# CH32L103 register map
Vendor: WCH Ltd.; File version: 1.3
Registers are 32-bit, read-write, reset 0x0 unless marked. A register's access mark holds for its fields unless they carry their own. Offsets are from the block's base; [hi:lo] are bit positions.

## LPTIM — Low-power timer
Base 0x40007C00
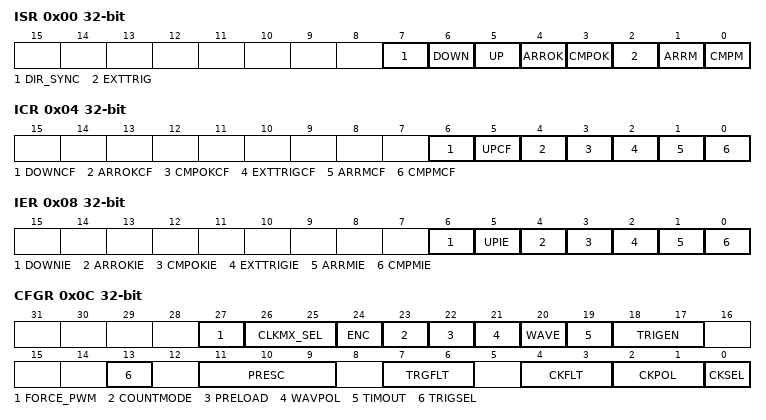
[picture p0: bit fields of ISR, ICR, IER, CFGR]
0x00 ISR ro — interrupt status register
  [7] DIR_SYNC — direction of count
  [6] DOWN — count down
  [5] UP — count-up
  [4] ARROK — Aoto-reload register data update successfully
  [3] CMPOK — compare register data update successfully
  [2] EXTTRIG — Edge event are triggerd externally
  [1] ARRM — DATA of Aoto-reload register and LPTIM_CNT match
  [0] CMPM — DATA of compare register and LPTIM_CNT match
0x04 ICR wo — interrupt clear register
  [6] DOWNCF — clear down flag
  [5] UPCF — clear up flag
  [4] ARROKCF — clear Aoto-reload register data update flag
  [3] CMPOKCF — clear compare register data update flag
  [2] EXTTRIGCF — clear Edge event are triggerd externally flag
  [1] ARRMCF — clear Aoto-reload register match flag
  [0] CMPMCF — clear compare register match flag
0x08 IER — interrupt enable register
  [6] DOWNIE — Down interrupt enable
  [5] UPIE — UP interrupt enable
  [4] ARROKIE — Aoto-reload register data update successfully interrupts enable
  [3] CMPOKIE — compare register data update successfully interrupts enable
  [2] EXTTRIGIE — Edge event are triggerd externally successfully interrupts enable
  [1] ARRMIE — Aoto-reload register match successfully interrupts enable
  [0] CMPMIE — compare register match successfully interrupts enable
0x0C CFGR — configuration register
  [27] FORCE_PWM — Forcing pwm output
  [26:25] CLKMX_SEL — clock selection
  [24] ENC — coder mode
  [23] COUNTMODE — count clock selection
  [22] PRELOAD — update mode control
  [21] WAVPOL — PWM polarity
  [20] WAVE — PWM
  [19] TIMOUT — TIMEOUT control
  [18:17] TRIGEN — trigger configuration
  [13] TRIGSEL — trigger source selection
  [11:9] PRESC — prescaler configuration
  [7:6] TRGFLT — digital filter for flip-flops
  [4:3] CKFLT — digital filter for ex-clock
  [2:1] CKPOL — configure effective edges
  [0] CKSEL — effective edge configuration
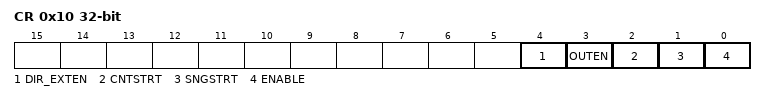
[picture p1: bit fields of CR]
0x10 CR — control register
  [4] DIR_EXTEN — externally trigger count direction enable
  [3] OUTEN — pwm output enable
  [2] CNTSTRT — start in continuous mode
  [1] SNGSTRT — start in one trigger mode
  [0] ENABLE — timer enable
0x14 CMP — compare register
  [15:0] CMP — compare value
0x18 ARR reset 0x1 — aoto-reload register
  [15:0] ARR — aoto-reload count value
0x1C CNT — COUNT register
  [15:0] COUNT — Timer count value

## USBPD — USBPD control register
Base 0x40027000
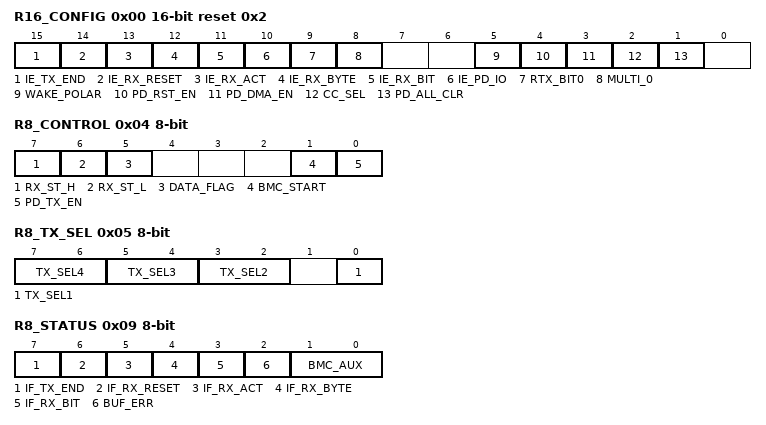
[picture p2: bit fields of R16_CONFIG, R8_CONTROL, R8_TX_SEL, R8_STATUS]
0x00 R16_CONFIG 16-bit reset 0x2 — PD configuration register
  [15] IE_TX_END — end of send interrupt enable
  [14] IE_RX_RESET — receive reset interrupt enable
  [13] IE_RX_ACT — receive finished interrupt enable
  [12] IE_RX_BYTE — receive byte interrupt enable
  [11] IE_RX_BIT — receive bit interrupt enable
  [10] IE_PD_IO — PD port interrupt enable
  [9] RTX_BIT0 — Send and receive the current value of shift register bit0
  [8] MULTI_0 — Receive a continuous multi-digit0 indication signal
  [5] WAKE_POLAR — wake-up level
  [4] PD_RST_EN — reset enable
  [3] PD_DMA_EN — PD_DMA enable
  [2] CC_SEL — communication port selection
  [1] PD_ALL_CLR — clear all interrupt enable
0x02 R16_BMC_CLK_CNT 16-bit — BMC sample clock counter
  [8:0] BMC_CLK_CNT — BMC sent/receive sample clock counter
0x04 R8_CONTROL 8-bit — sent/receive enable register
  [7] RX_ST_H — receive status high bit
  [6] RX_ST_L — receive status low bit
  [5] DATA_FLAG — data cache valid flag
  [1] BMC_START — BMC send a start signal
  [0] PD_TX_EN — sent/receive enable
0x05 R8_TX_SEL 8-bit — PD send sop selection register
  [7:6] TX_SEL4 — PD send type selection
  [5:4] TX_SEL3 — PD send type selection
  [3:2] TX_SEL2 — PD send type selection
  [0] TX_SEL1 — PD send type selection
0x06 R16_BMC_TX_SZ 16-bit — Total length sent
  [8:0] BMC_TX_SZ
0x08 R8_DATA_BUF 8-bit — DMA buffer data register
  [7:0] DATA_BUF — DMA DATA_BUFFER
0x09 R8_STATUS 8-bit access per field — PD interrupt flag register
  [7] IF_TX_END rw — Transmission completed interrupt flag
  [6] IF_RX_RESET rw — Receive reset interrupt flag
  [5] IF_RX_ACT rw — Receive completed interrupt flag
  [4] IF_RX_BYTE rw — Receive byte/SOP interrupt flag
  [3] IF_RX_BIT rw — Receive BIT/5BIT interrupt flag
  [2] BUF_ERR rw — BUFFER/DMA error interrupt flag
  [1:0] BMC_AUX ro — Indicating the current state
0x0A R16_BMC_BYTE_CNT 16-bit ro — byte count register
  [8:0] BMC_BYTE_CNT
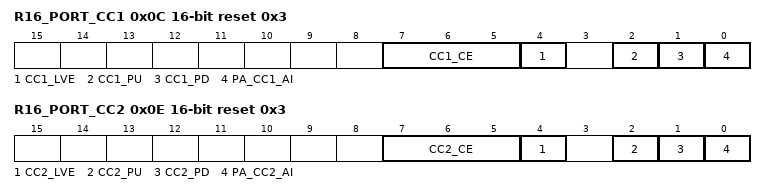
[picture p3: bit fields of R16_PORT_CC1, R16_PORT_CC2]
0x0C R16_PORT_CC1 16-bit reset 0x3 — port control register
  [7:5] CC1_CE — Enable port voltage comparator
  [4] CC1_LVE — port output lower voltage enable
  [2] CC1_PU — port pull-up current enable
  [1] CC1_PD — port pull-down resistor enable
  [0] PA_CC1_AI — port comparator simulates input
0x0E R16_PORT_CC2 16-bit reset 0x3 — port control register
  [7:5] CC2_CE — Enable port voltage comparator
  [4] CC2_LVE — port output lower voltage enable
  [2] CC2_PU — port pull-up current enable
  [1] CC2_PD — port pull-down resistor enable
  [0] PA_CC2_AI — port comparator simulates input
0x10 R16_DMA 16-bit — DMA cache start address register
  [15:0] USBPD_DMA_ADDR — USBPD_DMA cache address

## ESIG — ESIG configuration
Base 0x1FFFF7E0
0x00 FLACAP 16-bit ro — Flash capecity register
  [15:0] F_SIZE — F_SIZE/kByte
0x08 UNIID1 ro — UID register
  [31:0] U_ID — U_ID value
0x0C UNIID2 ro — UID register
  [31:0] U_ID — U_ID value
0x10 UNIID3 ro — Div register
  [31:0] AWU_APR — AWU_APR value
